VERSION "created by canmatrix"

NS_ :

BS_:

BU_: User ADB_PC_AC01 ADB_PC_BASE ADB_PC_BOX

BO_ 2155937856 AC01_Mode_Set_0_AC01: 1 User
 SG_ mode_0_AC01 : 0|8@1+ (1,0) [0|255] "" ADB_PC_AC01,User

BO_ 2155937857 AC01_Mode_Applied_0_AC01: 1 ADB_PC_AC01
 SG_ mode_0_AC01 : 0|8@1+ (1,0) [0|255] "" User

BO_ 2155937858 AC01_faults_0_AC01: 8 ADB_PC_AC01
 SG_ CABLE_1_2_L1_0_AC01 : 0|1@1+ (1,0) [0|1] "" User
 SG_ CABLE_1_3_L1_0_AC01 : 1|1@1+ (1,0) [0|1] "" User
 SG_ CABLE_1_2_L2_0_AC01 : 2|1@1+ (1,0) [0|1] "" User
 SG_ CABLE_1_3_L2_0_AC01 : 3|1@1+ (1,0) [0|1] "" User
 SG_ CABLE_1_2_L3_0_AC01 : 4|1@1+ (1,0) [0|1] "" User
 SG_ CABLE_1_3_L3_0_AC01 : 5|1@1+ (1,0) [0|1] "" User
 SG_ CABLE_4_5_L1_0_AC01 : 6|1@1+ (1,0) [0|1] "" User
 SG_ CABLE_4_6_L1_0_AC01 : 7|1@1+ (1,0) [0|1] "" User
 SG_ CABLE_4_5_L2_0_AC01 : 8|1@1+ (1,0) [0|1] "" User
 SG_ CABLE_4_6_L2_0_AC01 : 9|1@1+ (1,0) [0|1] "" User
 SG_ CABLE_4_5_L3_0_AC01 : 10|1@1+ (1,0) [0|1] "" User
 SG_ CABLE_4_6_L3_0_AC01 : 11|1@1+ (1,0) [0|1] "" User
 SG_ CABLE_1_4_L1_0_AC01 : 12|1@1+ (1,0) [0|1] "" User
 SG_ CABLE_1_4_L2_0_AC01 : 13|1@1+ (1,0) [0|1] "" User
 SG_ CABLE_1_4_L3_0_AC01 : 14|1@1+ (1,0) [0|1] "" User
 SG_ CABLE_2_3_DC_0_AC01 : 15|1@1+ (1,0) [0|1] "" User
 SG_ CABLE_5_6_DC_0_AC01 : 16|1@1+ (1,0) [0|1] "" User
 SG_ CABLE_3_5_DC_0_AC01 : 17|1@1+ (1,0) [0|1] "" User
 SG_ MODULE_1_RUNNING_0_AC01 : 18|1@1+ (1,0) [0|1] "" User
 SG_ MODULE_2_RUNNING_0_AC01 : 19|1@1+ (1,0) [0|1] "" User
 SG_ MODULE_3_RUNNING_0_AC01 : 20|1@1+ (1,0) [0|1] "" User
 SG_ MODULE_4_RUNNING_0_AC01 : 21|1@1+ (1,0) [0|1] "" User
 SG_ MODULE_5_RUNNING_0_AC01 : 22|1@1+ (1,0) [0|1] "" User
 SG_ MODULE_6_RUNNING_0_AC01 : 23|1@1+ (1,0) [0|1] "" User
 SG_ FILTER_1_RELAY_FAIL_0_AC01 : 24|1@1+ (1,0) [0|1] "" User
 SG_ FILTER_4_RELAY_FAIL_0_AC01 : 25|1@1+ (1,0) [0|1] "" User
 SG_ FILTER_1_RELAY_NOT_OFF_0_AC01 : 26|1@1+ (1,0) [0|1] "" User
 SG_ FILTER_4_RELAY_NOT_OFF_0_AC01 : 27|1@1+ (1,0) [0|1] "" User
 SG_ PRECHARGE_RELAY_CLOSING_0_AC01 : 28|1@1+ (1,0) [0|1] "" User
 SG_ PRECHARGE_RELAY_OPENING_0_AC01 : 29|1@1+ (1,0) [0|1] "" User
 SG_ FILTER_NOT_RUNNING_0_AC01 : 30|1@1+ (1,0) [0|1] "" User
 SG_ RECTIFIER_3P_NOT_RUNNING_0_AC01 : 31|1@1+ (1,0) [0|1] "" User
 SG_ AFE_NOT_OFF_0_AC01 : 32|1@1+ (1,0) [0|1] "" User
 SG_ FILTER_STOP_RUNNING_0_AC01 : 34|1@1+ (1,0) [0|1] "" User
 SG_ RECTIFIER_3P_STOP_RUNNING_0_AC01 : 35|1@1+ (1,0) [0|1] "" User
 SG_ AFE_PWM_NOT_RUNNING_0_AC01 : 36|1@1+ (1,0) [0|1] "" User
 SG_ AFE_PWM_STOP_RUNNING_0_AC01 : 37|1@1+ (1,0) [0|1] "" User
 SG_ BLEEDING_FAILED_0_AC01 : 38|1@1+ (1,0) [0|1] "" User
 SG_ FILTER_NOT_OFF_0_AC01 : 39|1@1+ (1,0) [0|1] "" User

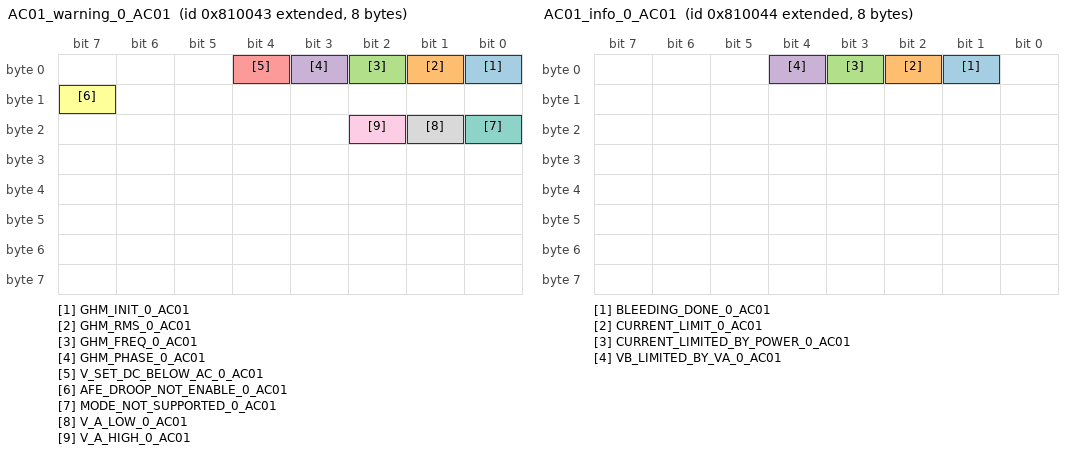
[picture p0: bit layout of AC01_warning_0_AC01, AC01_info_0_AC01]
BO_ 2155937859 AC01_warning_0_AC01: 8 ADB_PC_AC01
 SG_ GHM_INIT_0_AC01 : 0|1@1+ (1,0) [0|1] "" User
 SG_ GHM_RMS_0_AC01 : 1|1@1+ (1,0) [0|1] "" User
 SG_ GHM_FREQ_0_AC01 : 2|1@1+ (1,0) [0|1] "" User
 SG_ GHM_PHASE_0_AC01 : 3|1@1+ (1,0) [0|1] "" User
 SG_ V_SET_DC_BELOW_AC_0_AC01 : 4|1@1+ (1,0) [0|1] "" User
 SG_ AFE_DROOP_NOT_ENABLE_0_AC01 : 15|1@1+ (1,0) [0|1] "" User
 SG_ MODE_NOT_SUPPORTED_0_AC01 : 16|1@1+ (1,0) [0|1] "" User
 SG_ V_A_LOW_0_AC01 : 17|1@1+ (1,0) [0|1] "" User
 SG_ V_A_HIGH_0_AC01 : 18|1@1+ (1,0) [0|1] "" User

BO_ 2155937860 AC01_info_0_AC01: 8 ADB_PC_AC01
 SG_ BLEEDING_DONE_0_AC01 : 1|1@1+ (1,0) [0|1] "" User
 SG_ CURRENT_LIMIT_0_AC01 : 2|1@1+ (1,0) [0|1] "" User
 SG_ CURRENT_LIMITED_BY_POWER_0_AC01 : 3|1@1+ (1,0) [0|1] "" User
 SG_ VB_LIMITED_BY_VA_0_AC01 : 4|1@1+ (1,0) [0|1] "" User

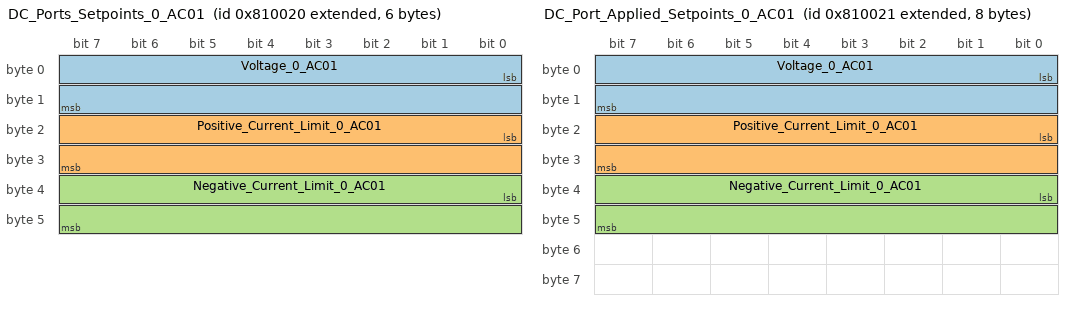
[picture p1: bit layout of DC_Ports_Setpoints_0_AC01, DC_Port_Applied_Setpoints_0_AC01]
BO_ 2155937824 DC_Ports_Setpoints_0_AC01: 6 User
 SG_ Voltage_0_AC01 : 0|16@1+ (0.1,0) [0|6553.5] "V" ADB_PC_AC01,User
 SG_ Positive_Current_Limit_0_AC01 : 16|16@1- (0.1,0) [-3276.8|3276.7] "A" ADB_PC_AC01,User
 SG_ Negative_Current_Limit_0_AC01 : 32|16@1- (0.1,0) [-3276.8|3276.7] "A" ADB_PC_AC01,User

BO_ 2155937825 DC_Port_Applied_Setpoints_0_AC01: 8 ADB_PC_AC01
 SG_ Voltage_0_AC01 : 0|16@1+ (0.1,0) [0|6553.5] "V" User
 SG_ Positive_Current_Limit_0_AC01 : 16|16@1- (0.1,0) [-3276.8|3276.7] "A" User
 SG_ Negative_Current_Limit_0_AC01 : 32|16@1- (0.1,0) [-3276.8|3276.7] "A" User

BO_ 2155937828 DC_Port_Measurements_0_AC01: 4 ADB_PC_AC01
 SG_ Voltage_0_AC01 : 0|16@1+ (0.1,0) [0|6553.5] "V" User
 SG_ Current_0_AC01 : 16|16@1- (0.1,0) [-3276.8|3276.7] "A" User

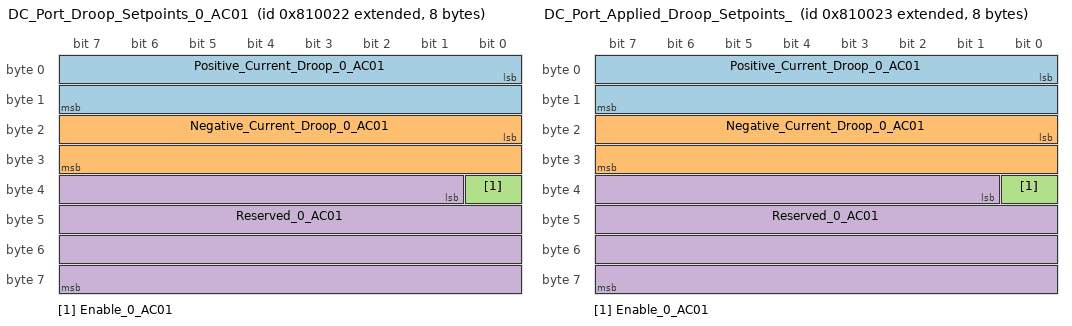
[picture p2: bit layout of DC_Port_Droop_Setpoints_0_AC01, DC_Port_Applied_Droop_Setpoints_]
BO_ 2155937826 DC_Port_Droop_Setpoints_0_AC01: 8 User
 SG_ Positive_Current_Droop_0_AC01 : 0|16@1+ (0.01,0) [0.00|655.35] "Ohm" ADB_PC_AC01,User
 SG_ Negative_Current_Droop_0_AC01 : 16|16@1+ (0.01,0) [0.00|655.35] "Ohm" ADB_PC_AC01,User
 SG_ Enable_0_AC01 : 32|1@1+ (1,0) [0|1] "" ADB_PC_AC01,User
 SG_ Reserved_0_AC01 : 33|31@1+ (1,0) [0|2147483647] "" ADB_PC_AC01,User

BO_ 2155937827 DC_Port_Applied_Droop_Setpoints_: 8 ADB_PC_AC01
 SG_ Positive_Current_Droop_0_AC01 : 0|16@1+ (0.01,0) [0.00|655.35] "Ohm" User
 SG_ Negative_Current_Droop_0_AC01 : 16|16@1+ (0.01,0) [0.00|655.35] "Ohm" User
 SG_ Enable_0_AC01 : 32|1@1+ (1,0) [0|1] "" User
 SG_ Reserved_0_AC01 : 33|31@1+ (1,0) [0|2147483647] "" User

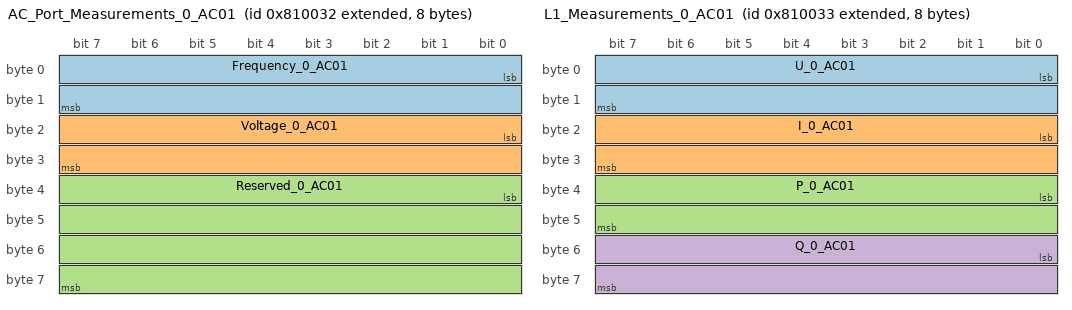
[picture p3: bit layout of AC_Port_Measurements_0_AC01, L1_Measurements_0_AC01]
BO_ 2155937842 AC_Port_Measurements_0_AC01: 8 ADB_PC_AC01
 SG_ Frequency_0_AC01 : 0|16@1+ (0.01,0) [0.00|655.35] "Hz" User
 SG_ Voltage_0_AC01 : 16|16@1+ (0.1,0) [0|6553.5] "V" User
 SG_ Reserved_0_AC01 : 32|32@1+ (1,0) [0|4294967295] "" User

BO_ 2155937843 L1_Measurements_0_AC01: 8 ADB_PC_AC01
 SG_ U_0_AC01 : 0|16@1- (0.1,0) [-3276.8|3276.7] "V" User
 SG_ I_0_AC01 : 16|16@1- (0.1,0) [-3276.8|3276.7] "A" User
 SG_ P_0_AC01 : 32|16@1- (0.1,0) [-3276.8|3276.7] "W" User
 SG_ Q_0_AC01 : 48|16@1- (0.1,0) [-3276.8|3276.7] "VAR" User,ADB_PC_AC01

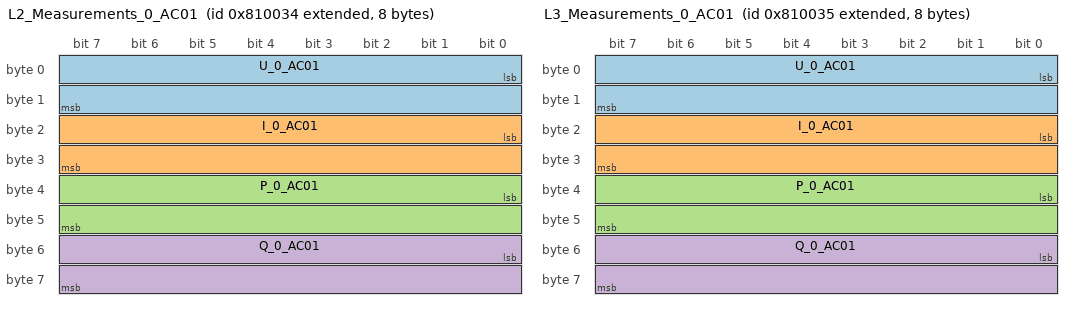
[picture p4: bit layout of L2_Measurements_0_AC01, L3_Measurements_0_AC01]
BO_ 2155937844 L2_Measurements_0_AC01: 8 ADB_PC_AC01
 SG_ U_0_AC01 : 0|16@1- (0.1,0) [-3276.8|3276.7] "V" User
 SG_ I_0_AC01 : 16|16@1- (0.1,0) [-3276.8|3276.7] "A" User
 SG_ P_0_AC01 : 32|16@1- (0.1,0) [-3276.8|3276.7] "W" User
 SG_ Q_0_AC01 : 48|16@1- (0.1,0) [-3276.8|3276.7] "VAR" User

BO_ 2155937845 L3_Measurements_0_AC01: 8 ADB_PC_AC01
 SG_ U_0_AC01 : 0|16@1- (0.1,0) [-3276.8|3276.7] "V" User
 SG_ I_0_AC01 : 16|16@1- (0.1,0) [-3276.8|3276.7] "A" User
 SG_ P_0_AC01 : 32|16@1- (0.1,0) [-3276.8|3276.7] "W" User
 SG_ Q_0_AC01 : 48|16@1- (0.1,0) [-3276.8|3276.7] "VAR" User

BO_ 2155937840 AC_Port_Setpoints_0_AC01: 8 User
 SG_ Q_0_AC01 : 0|16@1- (10,0) [-327680|327670] "VAR" ADB_PC_AC01
 SG_ Reserved_0_AC01 : 16|48@1+ (1,0) [0|281474976710655] "" ADB_PC_AC01

BO_ 2155937841 AC_Port_Applied_Setpoints_0_AC01: 8 ADB_PC_AC01
 SG_ Q_0_AC01 : 0|16@1- (10,0) [-327680|327670] "VAR" User
 SG_ Reserved_0_AC01 : 16|48@1+ (1,0) [0|281474976710655] "" User

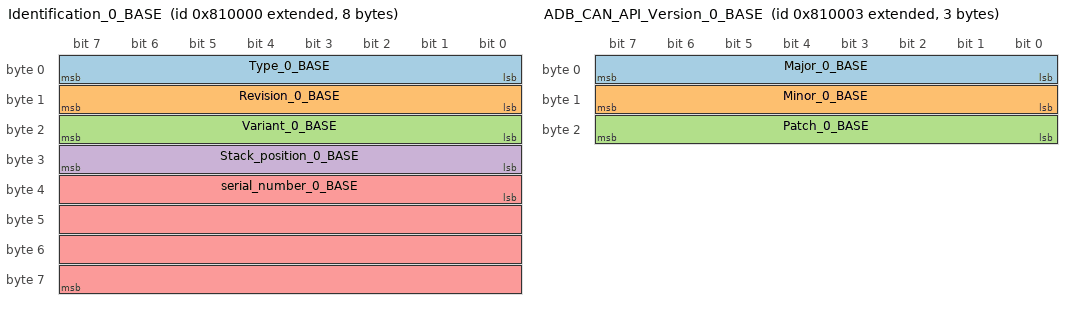
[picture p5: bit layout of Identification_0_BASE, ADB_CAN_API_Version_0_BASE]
BO_ 2155937792 Identification_0_BASE: 8 ADB_PC_BASE
 SG_ Type_0_BASE : 0|8@1+ (1,0) [0|255] "" User
 SG_ Revision_0_BASE : 8|8@1+ (1,0) [0|255] "" User
 SG_ Variant_0_BASE : 16|8@1+ (1,0) [0|255] "" User
 SG_ Stack_position_0_BASE : 24|8@1+ (1,0) [0|255] "" User,ADB_PC_BASE
 SG_ serial_number_0_BASE : 32|32@1+ (1,0) [0|4294967295] "" User

BO_ 2155937794 Firmware_UID_0_BASE: 8 ADB_PC_BASE
 SG_ UID_0_BASE : 0|64@1+ (1,0) [0|1.844674407370955E+019] "" User

BO_ 2155937793 Bootloader_UID_0_BASE: 8 ADB_PC_BASE
 SG_ UID_0_BASE : 0|64@1+ (1,0) [0|1.844674407370955E+019] "" User

BO_ 2155937795 ADB_CAN_API_Version_0_BASE: 3 ADB_PC_BASE
 SG_ Major_0_BASE : 0|8@1+ (1,0) [0|255] "" User
 SG_ Minor_0_BASE : 8|8@1+ (1,0) [0|255] "" User
 SG_ Patch_0_BASE : 16|8@1+ (1,0) [0|255] "" User

BO_ 2155937861 Stack_Control_0_BASE: 6 User
 SG_ Stack_position_0_BASE : 0|8@1+ (1,0) [0|255] "" ADB_PC_BASE
 SG_ reserved_0_BASE : 8|8@1+ (1,0) [0|255] "" ADB_PC_BASE
 SG_ SN_number_0_BASE : 16|32@1+ (1,0) [0|4294967295] "" ADB_PC_BASE

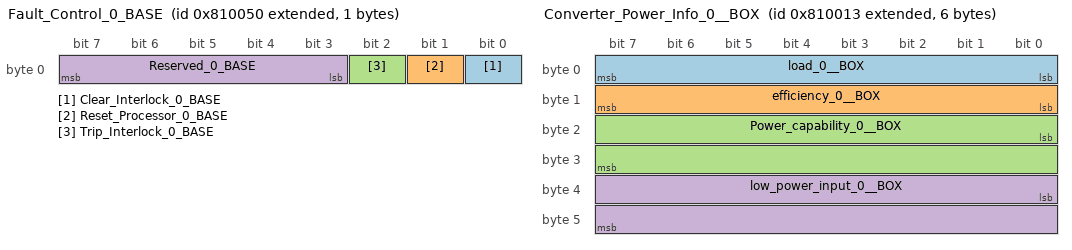
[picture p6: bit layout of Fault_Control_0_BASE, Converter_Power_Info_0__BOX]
BO_ 2155937872 Fault_Control_0_BASE: 1 User
 SG_ Clear_Interlock_0_BASE : 0|1@1+ (1,0) [0|1] "" ADB_PC_BASE
 SG_ Reset_Processor_0_BASE : 1|1@1+ (1,0) [0|1] "" ADB_PC_BASE
 SG_ Trip_Interlock_0_BASE : 2|1@1+ (1,0) [0|1] "" ADB_PC_BASE
 SG_ Reserved_0_BASE : 3|5@1+ (1,0) [0|31] "" ADB_PC_BASE

BO_ 2155937889 Factory_Control_0_BASE: 8 User
 SG_ Factory_mode_0_BASE : 0|1@1+ (1,0) [0|1] "" ADB_PC_BASE

BO_ 2155937810 Converter_Control_0__BOX: 1 User
 SG_ enable_0__BOX : 0|1@1+ (1,0) [0|1] "" ADB_PC_BOX

BO_ 2155937811 Converter_Power_Info_0__BOX: 6 ADB_PC_BOX
 SG_ load_0__BOX : 0|8@1+ (1,0) [0|255] "%" User
 SG_ efficiency_0__BOX : 8|8@1+ (1,0) [0|255] "%" User
 SG_ Power_capability_0__BOX : 16|16@1- (0.1,0) [-3276.8|3276.7] "kw" User
 SG_ low_power_input_0__BOX : 32|16@1- (0.01,0) [-327.68|327.67] "v" User

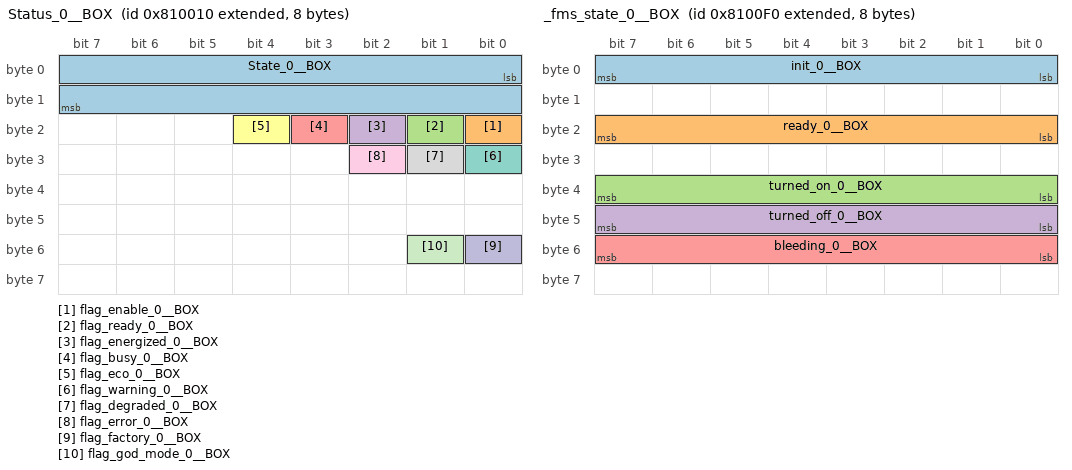
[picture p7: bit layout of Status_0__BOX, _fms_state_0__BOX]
BO_ 2155937808 Status_0__BOX: 8 ADB_PC_BOX
 SG_ State_0__BOX : 0|16@1+ (1,0) [0|65535] "" User
 SG_ flag_enable_0__BOX : 16|1@1+ (1,0) [0|1] "" User
 SG_ flag_ready_0__BOX : 17|1@1+ (1,0) [0|1] "" User
 SG_ flag_energized_0__BOX : 18|1@1+ (1,0) [0|1] "" User
 SG_ flag_busy_0__BOX : 19|1@1+ (1,0) [0|1] "" User
 SG_ flag_eco_0__BOX : 20|1@1+ (1,0) [0|1] "" User
 SG_ flag_warning_0__BOX : 24|1@1+ (1,0) [0|1] "" User
 SG_ flag_degraded_0__BOX : 25|1@1+ (1,0) [0|1] "" User
 SG_ flag_error_0__BOX : 26|1@1+ (1,0) [0|1] "" User
 SG_ flag_factory_0__BOX : 48|1@1+ (1,0) [0|1] "" User
 SG_ flag_god_mode_0__BOX : 49|1@1+ (1,0) [0|1] "" User

BO_ 2155938032 _fms_state_0__BOX: 8 ADB_PC_BOX
 SG_ init_0__BOX : 0|8@1+ (1,0) [0|255] "" User
 SG_ ready_0__BOX : 16|8@1+ (1,0) [0|255] "" User
 SG_ turned_on_0__BOX : 32|8@1+ (1,0) [0|255] "" User
 SG_ turned_off_0__BOX : 40|8@1+ (1,0) [0|255] "" User
 SG_ bleeding_0__BOX : 48|8@1+ (1,0) [0|255] "" User

BO_ 2155937809 Faults_0__BOX: 8 ADB_PC_BOX
 SG_ internal_0__BOX : 0|1@1+ (1,0) [0|1] "" User
 SG_ external_0__BOX : 1|1@1+ (1,0) [0|1] "" User
 SG_ system_0__BOX : 2|1@1+ (1,0) [0|1] "" User
 SG_ EEPROM_failure_0__BOX : 3|1@1+ (1,0) [0|1] "" User
 SG_ wrong_nfo_0__BOX : 4|1@1+ (1,0) [0|1] "" User
 SG_ Measurement_system_failure_0__BO : 5|1@1+ (1,0) [0|1] "" User
 SG_ PLL_not_locked_0__BOX : 6|1@1+ (1,0) [0|1] "" User
 SG_ overtemperature_0__BOX : 7|1@1+ (1,0) [0|1] "" User
 SG_ fan_stuck_0__BOX : 8|1@1+ (1,0) [0|1] "" User
 SG_ dead_module_0__BOX : 9|1@1+ (1,0) [0|1] "" User
 SG_ keep_alive_not_serv_internal_0__ : 10|1@1+ (1,0) [0|1] "" User
 SG_ error_temperature_0__BOX : 11|1@1+ (1,0) [0|1] "" User
 SG_ internal_modules_ready_0__BOX : 12|1@1+ (1,0) [0|1] "" User
 SG_ internal_modules_can_api_0__BOX : 13|1@1+ (1,0) [0|1] "" User
 SG_ internal_modules_missing_0__BOX : 14|1@1+ (1,0) [0|1] "" User
 SG_ internal_modules_wrong_0__BOX : 15|1@1+ (1,0) [0|1] "" User
 SG_ internal_modules_stack_0__BOX : 16|1@1+ (1,0) [0|1] "" User
 SG_ internal_modules_init_0__BOX : 17|1@1+ (1,0) [0|1] "" User
 SG_ wrong_revision_0__BOX : 18|1@1+ (1,0) [0|1] "" User
 SG_ v_in_low_0__BOX : 19|1@1+ (1,0) [0|1] "" User
 SG_ v_in_critical_0__BOX : 20|1@1+ (1,0) [0|1] "" User
 SG_ keep_alive_not_serv_0__BOX : 21|1@1+ (1,0) [0|1] "" User

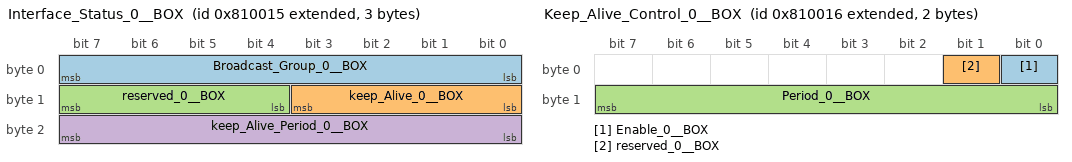
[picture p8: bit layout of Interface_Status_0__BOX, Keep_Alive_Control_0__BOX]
BO_ 2155937813 Interface_Status_0__BOX: 3 ADB_PC_BOX
 SG_ Broadcast_Group_0__BOX : 0|8@1+ (1,0) [0|30] "" User
 SG_ keep_Alive_0__BOX : 8|4@1+ (1,0) [0|15] "" User
 SG_ reserved_0__BOX : 12|4@1+ (1,0) [0|15] "" User
 SG_ keep_Alive_Period_0__BOX : 16|8@1+ (0.1,0) [0|25.5] "s" User

BO_ 2155937814 Keep_Alive_Control_0__BOX: 2 User
 SG_ Enable_0__BOX : 0|1@1+ (1,0) [0|1] "" ADB_PC_BOX
 SG_ reserved_0__BOX : 1|1@1+ (1,0) [0|1] "" User
 SG_ Period_0__BOX : 8|8@1+ (0.1,0) [0|25.5] "s" User

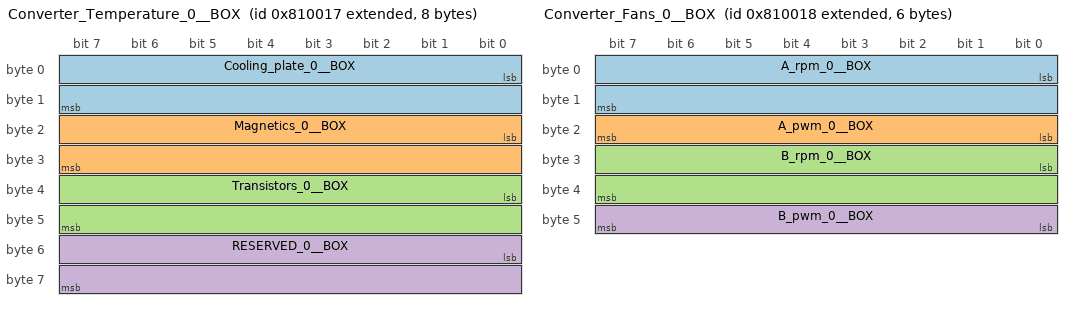
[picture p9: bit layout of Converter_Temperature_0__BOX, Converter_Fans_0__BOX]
BO_ 2155937815 Converter_Temperature_0__BOX: 8 ADB_PC_BOX
 SG_ Cooling_plate_0__BOX : 0|16@1- (0.01,0) [-327.68|327.67] "°C" User
 SG_ Magnetics_0__BOX : 16|16@1- (0.01,0) [-327.68|327.67] "°C" User
 SG_ Transistors_0__BOX : 32|16@1- (0.01,0) [-327.68|327.67] "°C" User
 SG_ RESERVED_0__BOX : 48|16@1- (0.01,0) [-327.68|327.67] "°C" User

BO_ 2155937816 Converter_Fans_0__BOX: 6 ADB_PC_BOX
 SG_ A_rpm_0__BOX : 0|16@1+ (1,0) [0|65535] "rpm" User
 SG_ A_pwm_0__BOX : 16|8@1+ (1,0) [0|255] "%" User
 SG_ B_rpm_0__BOX : 24|16@1+ (1,0) [0|65535] "rpm" User
 SG_ B_pwm_0__BOX : 40|8@1+ (1,0) [0|255] "%" User

BO_ 2155937817 Keep_Alive_Feed_0__BOX: 1 User
 SG_ feed_0__BOX : 0|1@1+ (1,0) [0|1] "" ADB_PC_BOX

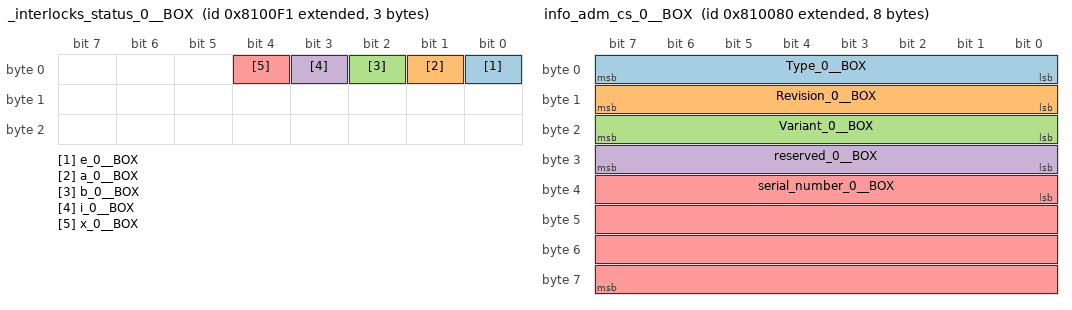
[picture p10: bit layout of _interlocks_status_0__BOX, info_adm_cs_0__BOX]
BO_ 2155938033 _interlocks_status_0__BOX: 3 ADB_PC_BOX
 SG_ e_0__BOX : 0|1@1+ (1,0) [0|1] "" User
 SG_ a_0__BOX : 1|1@1+ (1,0) [0|1] "" User
 SG_ b_0__BOX : 2|1@1+ (1,0) [0|1] "" User
 SG_ i_0__BOX : 3|1@1+ (1,0) [0|1] "" User
 SG_ x_0__BOX : 4|1@1+ (1,0) [0|1] "" User

BO_ 2155937812 Broadcast_Group_Control_0__BOX: 1 User
 SG_ Group_ID_0__BOX : 0|8@1+ (1,0) [0|255] "" ADB_PC_BOX

BO_ 2155937920 info_adm_cs_0__BOX: 8 ADB_PC_BOX
 SG_ Type_0__BOX : 0|8@1+ (1,0) [0|255] "" User
 SG_ Revision_0__BOX : 8|8@1+ (1,0) [0|255] "" User
 SG_ Variant_0__BOX : 16|8@1+ (1,0) [0|255] "" User
 SG_ reserved_0__BOX : 24|8@1+ (1,0) [0|255] "" User
 SG_ serial_number_0__BOX : 32|32@1+ (1,0) [0|4294967295] "" User

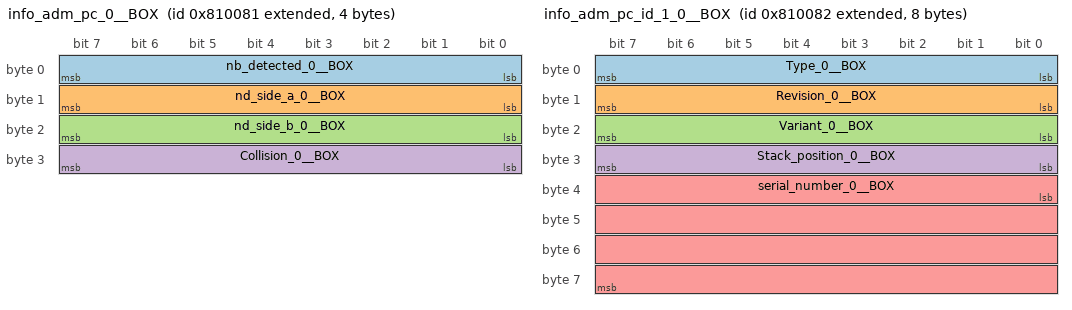
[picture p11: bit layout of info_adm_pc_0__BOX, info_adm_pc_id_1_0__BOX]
BO_ 2155937921 info_adm_pc_0__BOX: 4 ADB_PC_BOX
 SG_ nb_detected_0__BOX : 0|8@1+ (1,0) [0|255] "" User
 SG_ nd_side_a_0__BOX : 8|8@1+ (1,0) [0|255] "" User
 SG_ nd_side_b_0__BOX : 16|8@1+ (1,0) [0|255] "" User
 SG_ Collision_0__BOX : 24|8@1+ (1,0) [0|255] "" User

BO_ 2155937922 info_adm_pc_id_1_0__BOX: 8 ADB_PC_BOX
 SG_ Type_0__BOX : 0|8@1+ (1,0) [0|255] "" User
 SG_ Revision_0__BOX : 8|8@1+ (1,0) [0|255] "" User
 SG_ Variant_0__BOX : 16|8@1+ (1,0) [0|255] "" User
 SG_ Stack_position_0__BOX : 24|8@1+ (1,0) [0|255] "" User
 SG_ serial_number_0__BOX : 32|32@1+ (1,0) [0|4294967295] "" User

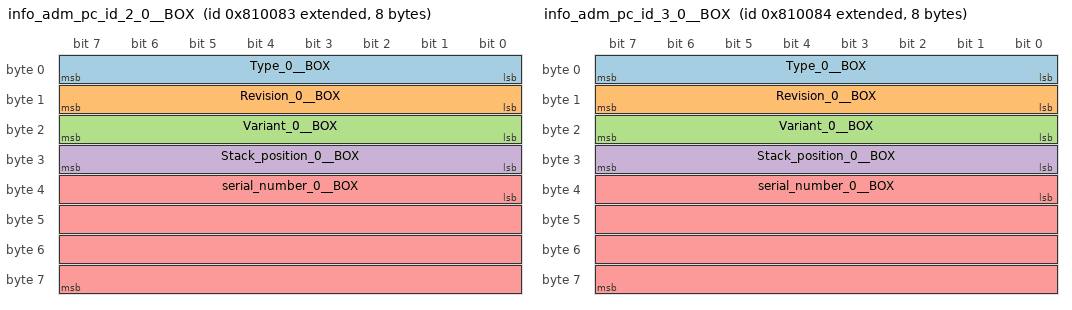
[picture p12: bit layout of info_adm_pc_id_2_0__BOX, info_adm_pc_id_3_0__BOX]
BO_ 2155937923 info_adm_pc_id_2_0__BOX: 8 ADB_PC_BOX
 SG_ Type_0__BOX : 0|8@1+ (1,0) [0|255] "" User
 SG_ Revision_0__BOX : 8|8@1+ (1,0) [0|255] "" User
 SG_ Variant_0__BOX : 16|8@1+ (1,0) [0|255] "" User
 SG_ Stack_position_0__BOX : 24|8@1+ (1,0) [0|255] "" User
 SG_ serial_number_0__BOX : 32|32@1+ (1,0) [0|4294967295] "" User

BO_ 2155937924 info_adm_pc_id_3_0__BOX: 8 ADB_PC_BOX
 SG_ Type_0__BOX : 0|8@1+ (1,0) [0|255] "" User
 SG_ Revision_0__BOX : 8|8@1+ (1,0) [0|255] "" User
 SG_ Variant_0__BOX : 16|8@1+ (1,0) [0|255] "" User
 SG_ Stack_position_0__BOX : 24|8@1+ (1,0) [0|255] "" User
 SG_ serial_number_0__BOX : 32|32@1+ (1,0) [0|4294967295] "" User

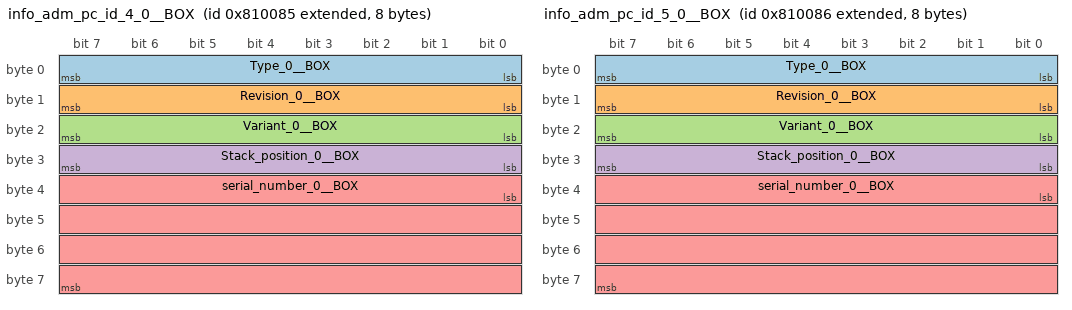
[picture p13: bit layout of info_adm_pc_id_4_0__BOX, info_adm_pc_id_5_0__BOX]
BO_ 2155937925 info_adm_pc_id_4_0__BOX: 8 ADB_PC_BOX
 SG_ Type_0__BOX : 0|8@1+ (1,0) [0|255] "" User
 SG_ Revision_0__BOX : 8|8@1+ (1,0) [0|255] "" User
 SG_ Variant_0__BOX : 16|8@1+ (1,0) [0|255] "" User
 SG_ Stack_position_0__BOX : 24|8@1+ (1,0) [0|255] "" User
 SG_ serial_number_0__BOX : 32|32@1+ (1,0) [0|4294967295] "" User

BO_ 2155937926 info_adm_pc_id_5_0__BOX: 8 ADB_PC_BOX
 SG_ Type_0__BOX : 0|8@1+ (1,0) [0|255] "" User
 SG_ Revision_0__BOX : 8|8@1+ (1,0) [0|255] "" User
 SG_ Variant_0__BOX : 16|8@1+ (1,0) [0|255] "" User
 SG_ Stack_position_0__BOX : 24|8@1+ (1,0) [0|255] "" User
 SG_ serial_number_0__BOX : 32|32@1+ (1,0) [0|4294967295] "" User

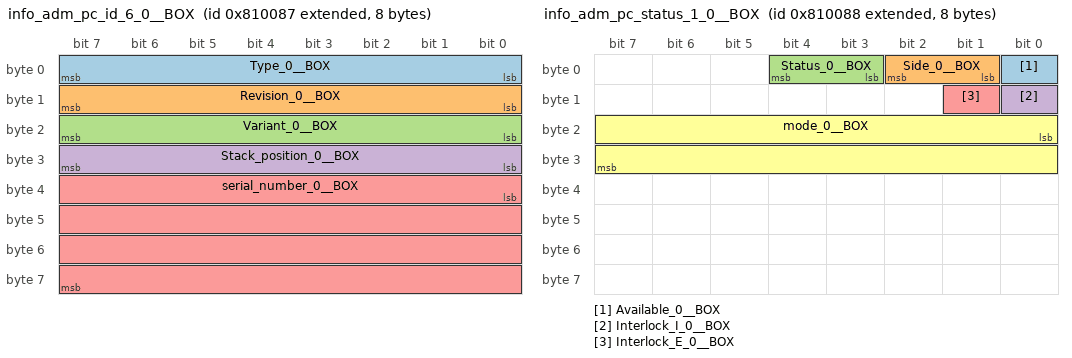
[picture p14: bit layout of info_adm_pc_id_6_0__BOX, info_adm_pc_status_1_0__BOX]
BO_ 2155937927 info_adm_pc_id_6_0__BOX: 8 ADB_PC_BOX
 SG_ Type_0__BOX : 0|8@1+ (1,0) [0|255] "" User
 SG_ Revision_0__BOX : 8|8@1+ (1,0) [0|255] "" User
 SG_ Variant_0__BOX : 16|8@1+ (1,0) [0|255] "" User
 SG_ Stack_position_0__BOX : 24|8@1+ (1,0) [0|255] "" User
 SG_ serial_number_0__BOX : 32|32@1+ (1,0) [0|4294967295] "" User

BO_ 2155937928 info_adm_pc_status_1_0__BOX: 8 ADB_PC_BOX
 SG_ Available_0__BOX : 0|1@1+ (1,0) [0|1] "" User
 SG_ Side_0__BOX : 1|2@1+ (1,0) [0|3] "" User
 SG_ Status_0__BOX : 3|2@1+ (1,0) [0|3] "" User
 SG_ Interlock_I_0__BOX : 8|1@1+ (1,0) [0|1] "" User
 SG_ Interlock_E_0__BOX : 9|1@1+ (1,0) [0|1] "" User
 SG_ mode_0__BOX : 16|16@1+ (1,0) [0|65535] "" User

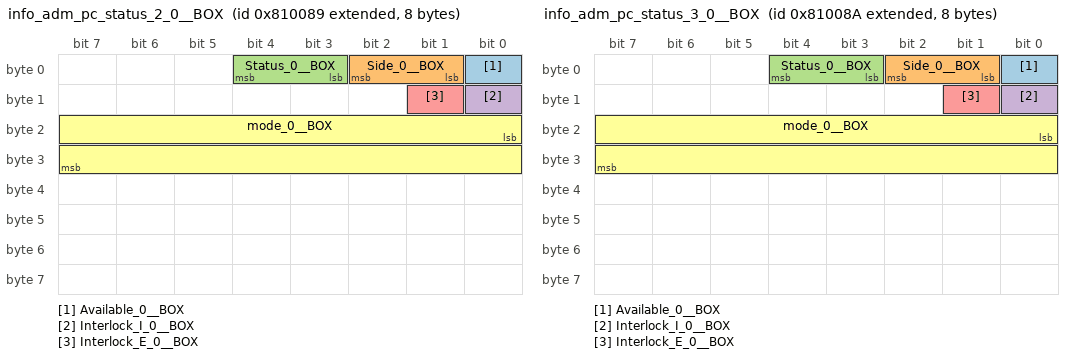
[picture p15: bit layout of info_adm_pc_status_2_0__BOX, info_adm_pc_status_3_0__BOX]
BO_ 2155937929 info_adm_pc_status_2_0__BOX: 8 ADB_PC_BOX
 SG_ Available_0__BOX : 0|1@1+ (1,0) [0|1] "" User
 SG_ Side_0__BOX : 1|2@1+ (1,0) [0|3] "" User
 SG_ Status_0__BOX : 3|2@1+ (1,0) [0|3] "" User
 SG_ Interlock_I_0__BOX : 8|1@1+ (1,0) [0|1] "" User
 SG_ Interlock_E_0__BOX : 9|1@1+ (1,0) [0|1] "" User
 SG_ mode_0__BOX : 16|16@1+ (1,0) [0|65535] "" User

BO_ 2155937930 info_adm_pc_status_3_0__BOX: 8 ADB_PC_BOX
 SG_ Available_0__BOX : 0|1@1+ (1,0) [0|1] "" User
 SG_ Side_0__BOX : 1|2@1+ (1,0) [0|3] "" User
 SG_ Status_0__BOX : 3|2@1+ (1,0) [0|3] "" User
 SG_ Interlock_I_0__BOX : 8|1@1+ (1,0) [0|1] "" User
 SG_ Interlock_E_0__BOX : 9|1@1+ (1,0) [0|1] "" User
 SG_ mode_0__BOX : 16|16@1+ (1,0) [0|65535] "" User

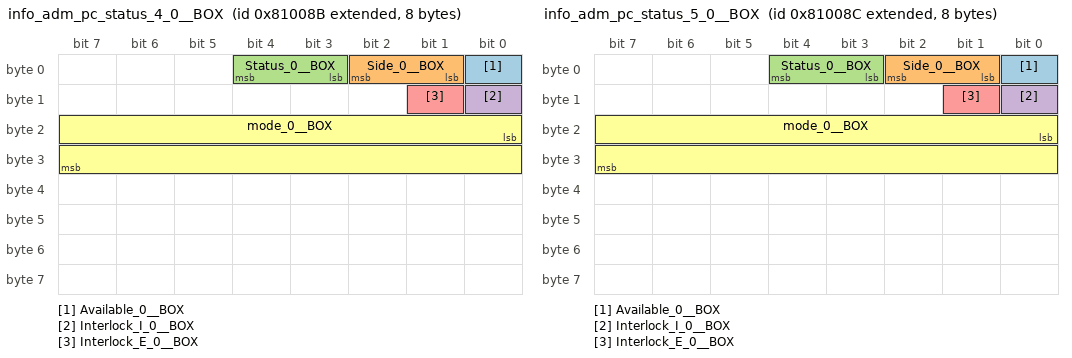
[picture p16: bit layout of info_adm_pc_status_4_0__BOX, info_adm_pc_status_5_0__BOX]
BO_ 2155937931 info_adm_pc_status_4_0__BOX: 8 ADB_PC_BOX
 SG_ Available_0__BOX : 0|1@1+ (1,0) [0|1] "" User
 SG_ Side_0__BOX : 1|2@1+ (1,0) [0|3] "" User
 SG_ Status_0__BOX : 3|2@1+ (1,0) [0|3] "" User
 SG_ Interlock_I_0__BOX : 8|1@1+ (1,0) [0|1] "" User
 SG_ Interlock_E_0__BOX : 9|1@1+ (1,0) [0|1] "" User
 SG_ mode_0__BOX : 16|16@1+ (1,0) [0|65535] "" User

BO_ 2155937932 info_adm_pc_status_5_0__BOX: 8 ADB_PC_BOX
 SG_ Available_0__BOX : 0|1@1+ (1,0) [0|1] "" User
 SG_ Side_0__BOX : 1|2@1+ (1,0) [0|3] "" User
 SG_ Status_0__BOX : 3|2@1+ (1,0) [0|3] "" User
 SG_ Interlock_I_0__BOX : 8|1@1+ (1,0) [0|1] "" User
 SG_ Interlock_E_0__BOX : 9|1@1+ (1,0) [0|1] "" User
 SG_ mode_0__BOX : 16|16@1+ (1,0) [0|65535] "" User

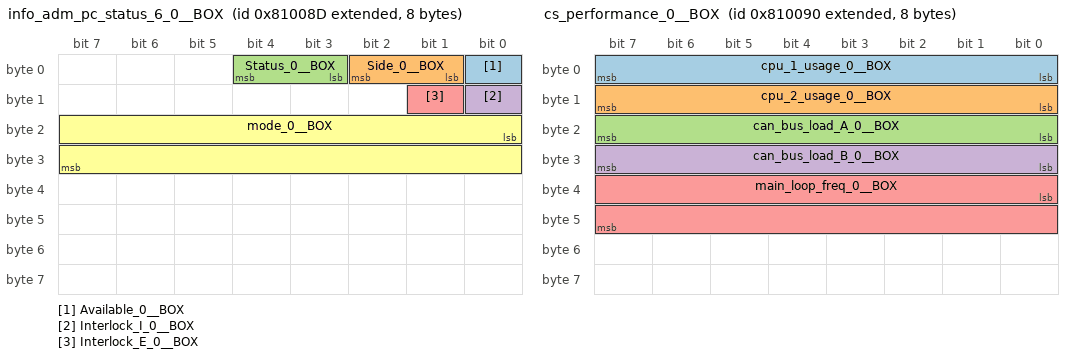
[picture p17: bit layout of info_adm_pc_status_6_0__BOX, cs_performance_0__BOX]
BO_ 2155937933 info_adm_pc_status_6_0__BOX: 8 ADB_PC_BOX
 SG_ Available_0__BOX : 0|1@1+ (1,0) [0|1] "" User
 SG_ Side_0__BOX : 1|2@1+ (1,0) [0|3] "" User
 SG_ Status_0__BOX : 3|2@1+ (1,0) [0|3] "" User
 SG_ Interlock_I_0__BOX : 8|1@1+ (1,0) [0|1] "" User
 SG_ Interlock_E_0__BOX : 9|1@1+ (1,0) [0|1] "" User
 SG_ mode_0__BOX : 16|16@1+ (1,0) [0|65535] "" User

BO_ 2155937936 cs_performance_0__BOX: 8 ADB_PC_BOX
 SG_ cpu_1_usage_0__BOX : 0|8@1+ (1,0) [0|255] "%" User
 SG_ cpu_2_usage_0__BOX : 8|8@1+ (1,0) [0|255] "%" User
 SG_ can_bus_load_A_0__BOX : 16|8@1+ (1,0) [0|255] "%" User
 SG_ can_bus_load_B_0__BOX : 24|8@1+ (1,0) [0|255] "%" User
 SG_ main_loop_freq_0__BOX : 32|16@1+ (1,0) [0|65535] "Hz" User

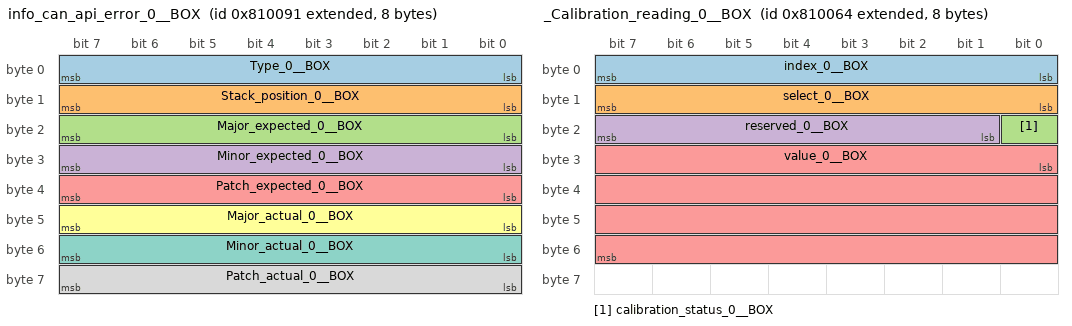
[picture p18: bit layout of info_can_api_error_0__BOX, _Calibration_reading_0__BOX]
BO_ 2155937937 info_can_api_error_0__BOX: 8 ADB_PC_BOX
 SG_ Type_0__BOX : 0|8@1+ (1,0) [0|255] "" User
 SG_ Stack_position_0__BOX : 8|8@1+ (1,0) [0|255] "" User
 SG_ Major_expected_0__BOX : 16|8@1+ (1,0) [0|255] "" User
 SG_ Minor_expected_0__BOX : 24|8@1+ (1,0) [0|255] "" User
 SG_ Patch_expected_0__BOX : 32|8@1+ (1,0) [0|255] "" User
 SG_ Major_actual_0__BOX : 40|8@1+ (1,0) [0|255] "" User
 SG_ Minor_actual_0__BOX : 48|8@1+ (1,0) [0|255] "" User
 SG_ Patch_actual_0__BOX : 56|8@1+ (1,0) [0|255] "" User

BO_ 2155937890 _Calibration_writing_0__BOX: 6 User
 SG_ index_0__BOX : 0|8@1+ (1,0) [0|255] "" ADB_PC_BOX,User
 SG_ select_0__BOX : 8|8@1+ (1,0) [0|255] "" ADB_PC_BOX,User
 SG_ value_0__BOX : 16|32@1- (0.0001,0) [-214748.3648|214748.3647] "" ADB_PC_BOX,User

BO_ 2155937891 _Calibration_reading_cmd_0__BOX: 2 User
 SG_ index_0__BOX : 0|8@1+ (1,0) [0|255] "" ADB_PC_BOX
 SG_ select_0__BOX : 8|8@1+ (1,0) [0|255] "" ADB_PC_BOX

BO_ 2155937892 _Calibration_reading_0__BOX: 8 ADB_PC_BOX
 SG_ index_0__BOX : 0|8@1+ (1,0) [0|255] "" User
 SG_ select_0__BOX : 8|8@1+ (1,0) [0|255] "" User
 SG_ calibration_status_0__BOX : 16|1@1+ (1,0) [0|1] "" User
 SG_ reserved_0__BOX : 17|7@1+ (1,0) [0|127] "" User
 SG_ value_0__BOX : 24|32@1- (0.0001,0) [-214748.3648|214748.3647] "" User

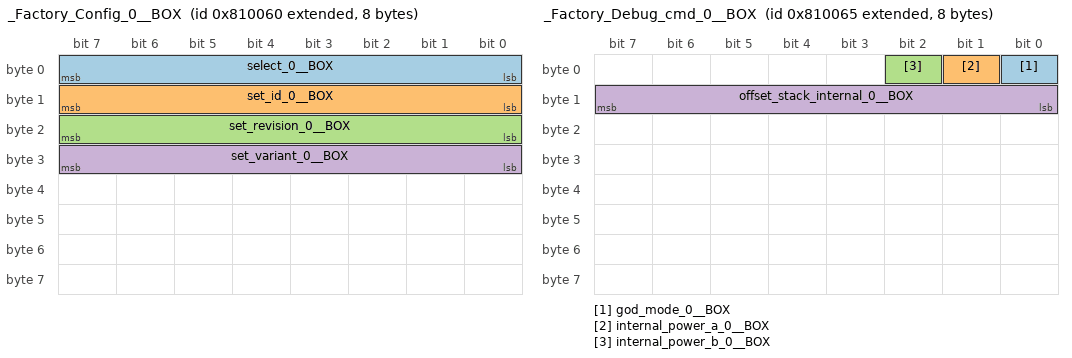
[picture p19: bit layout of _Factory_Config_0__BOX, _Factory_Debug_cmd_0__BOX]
BO_ 2155937888 _Factory_Config_0__BOX: 8 User
 SG_ select_0__BOX : 0|8@1+ (1,0) [0|255] "" ADB_PC_BOX
 SG_ set_id_0__BOX : 8|8@1+ (1,0) [0|255] "" ADB_PC_BOX
 SG_ set_revision_0__BOX : 16|8@1+ (1,0) [0|255] "" ADB_PC_BOX
 SG_ set_variant_0__BOX : 24|8@1+ (1,0) [0|255] "" ADB_PC_BOX

BO_ 2155937893 _Factory_Debug_cmd_0__BOX: 8 User
 SG_ god_mode_0__BOX : 0|1@1+ (1,0) [0|1] "" ADB_PC_BOX
 SG_ internal_power_a_0__BOX : 1|1@1+ (1,0) [0|1] "" ADB_PC_BOX
 SG_ internal_power_b_0__BOX : 2|1@1+ (1,0) [0|1] "" ADB_PC_BOX
 SG_ offset_stack_internal_0__BOX : 8|8@1+ (1,0) [0|255] "offset" ADB_PC_BOX

CM_ BO_ 2155937856  "Set the mode of AC01";
CM_ BO_ 2155937857  "read back the modes";
CM_ BO_ 2155937858  "AC01 Critical and Error Faults";
CM_ BO_ 2155937859  "AC01 Warning";
CM_ BO_ 2155937860  "AC01 Info";
CM_ BO_ 2155937824  "The setpoints control the behaviour of the DC Port of the AC01. The AC01 operates this port in CVCC mode";
CM_ BO_ 2155937825  "The setpoints that are currently used by the AC01. This message allows to validate that the setpoints have been properly applied.";
CM_ BO_ 2155937828  "Measurements of the DC Bus";
CM_ BO_ 2155937826  "Setpoints for applying Droop on the DC Port. Droop is needed for paralleling multiple AC01";
CM_ BO_ 2155937827  "Droop setpoints that are applied by the AC01";
CM_ BO_ 2155937842  "Mesured values of the Grid connection";
CM_ BO_ 2155937843  "Measurements for L1 of the AC port";
CM_ BO_ 2155937844  "Measurements for L2 of the AC port";
CM_ BO_ 2155937845  "Measurements for L3 of the AC port";
CM_ BO_ 2155937840  "Setpoints to apply to the AC Port";
CM_ BO_ 2155937841  "Setpoints that are currently being applied to the the AC Port";
CM_ BO_ 2155937792  "Identification of the device";
CM_ BO_ 2155937794  "Unique Identifier of the Firmware used on this module";
CM_ BO_ 2155937793  "Unique Identifier of the Bootloader used on this module";
CM_ BO_ 2155937795  "This message declares the version of the API that is provided by the converter. The version follows newer convention, as this file is an API definition, patch does not apply";
CM_ BO_ 2155937861  "Module stack control";
CM_ BO_ 2155937872  "Fault Control: actions to clear faults and reset the system";
CM_ BO_ 2155937889  "Control the system flags";
CM_ BO_ 2155937810  "box commands";
CM_ BO_ 2155937811  "Converter power info";
CM_ BO_ 2155937808  "General Status of the converter";
CM_ BO_ 2155938032  "FSm status for debug";
CM_ BO_ 2155937809  "Fault bitfield";
CM_ BO_ 2155937813  "interface status";
CM_ BO_ 2155937814  "Configure the Heartbeat for the Module. The 'Trip interlock' and 'Heartbeat Period' only apply if the heartbeat signals are enabled";
CM_ BO_ 2155937815  "Readouts of the converter temperature sensors";
CM_ BO_ 2155937816  "Readouts of the converter fans";
CM_ BO_ 2155937817  "keep alive feeding";
CM_ BO_ 2155938033  "BOX interlock status used for debug ";
CM_ BO_ 2155937812  "Configure the broadcast group that the module belongs to.";
CM_ BO_ 2155937920  "Contains the Group ID of the device";
CM_ BO_ 2155937921  "Contains the Group ID of the device";
CM_ BO_ 2155937922  "Contains the Group ID of the device";
CM_ BO_ 2155937923  "Contains the Group ID of the device";
CM_ BO_ 2155937924  "Contains the Group ID of the device";
CM_ BO_ 2155937925  "Contains the Group ID of the device";
CM_ BO_ 2155937926  "Contains the Group ID of the device";
CM_ BO_ 2155937927  "Contains the Group ID of the device";
CM_ BO_ 2155937928  "Status of internal modules";
CM_ BO_ 2155937929  "Status of internal modules";
CM_ BO_ 2155937930  "Status of internal modules";
CM_ BO_ 2155937931  "Status of internal modules";
CM_ BO_ 2155937932  "Status of internal modules";
CM_ BO_ 2155937933  "Status of internal modules";
CM_ BO_ 2155937936  "Status of internal modules";
CM_ BO_ 2155937937  "debug - Allow to knwow  what module has wrong can api";
CM_ BO_ 2155937890  "Calibration control (factory mode need to be set)";
CM_ BO_ 2155937891  "Calibration reading cmd (factory mode need to be set)";
CM_ BO_ 2155937892  "Calibration reading cmd (factory mode need to be set)";
CM_ BO_ 2155937888  "factory setting of controller and boxs";
CM_ BO_ 2155937893  "factory debug cmd, need factory mode flag set to 1";

CM_ SG_ 2155937856 mode_0_AC01 "require mode";
CM_ SG_ 2155937857 mode_0_AC01 "actual mode";
CM_ SG_ 2155937858 CABLE_1_2_L1_0_AC01 "DMF1(1).L1  BP25(2).U mismatch";
CM_ SG_ 2155937858 CABLE_1_3_L1_0_AC01 "DMF1(1).L1  BP25(3).U mismatch";
CM_ SG_ 2155937858 CABLE_1_2_L2_0_AC01 "DMF1(1).L2  BP25(2).V mismatch";
CM_ SG_ 2155937858 CABLE_1_3_L2_0_AC01 "DMF1(1).L2  BP25(3).V mismatch";
CM_ SG_ 2155937858 CABLE_1_2_L3_0_AC01 "DMF1(1).L3  BP25(2).W mismatch";
CM_ SG_ 2155937858 CABLE_1_3_L3_0_AC01 "DMF1(1).L3  BP25(3).W mismatch";
CM_ SG_ 2155937858 CABLE_4_5_L1_0_AC01 "DMF1(4).L1  BP25(5).U mismatch";
CM_ SG_ 2155937858 CABLE_4_6_L1_0_AC01 "DMF1(4).L1  BP25(6).U mismatch";
CM_ SG_ 2155937858 CABLE_4_5_L2_0_AC01 "DMF1(4).L2  BP25(5).V mismatch";
CM_ SG_ 2155937858 CABLE_4_6_L2_0_AC01 "DMF1(4).L2  BP25(6).V mismatch";
CM_ SG_ 2155937858 CABLE_4_5_L3_0_AC01 "DMF1(4).L3  BP25(5).W mismatch";
CM_ SG_ 2155937858 CABLE_4_6_L3_0_AC01 "DMF1(4).L3  BP25(6).W mismatch";
CM_ SG_ 2155937858 CABLE_1_4_L1_0_AC01 "Grid L1  DMF1(1).in vs DMF1(4).in mismatch";
CM_ SG_ 2155937858 CABLE_1_4_L2_0_AC01 "Grid L2  DMF1(1).in vs DMF1(4).in mismatch";
CM_ SG_ 2155937858 CABLE_1_4_L3_0_AC01 "Grid L3 - DMF1(1).in vs DMF1(4).in mismatch";
CM_ SG_ 2155937858 CABLE_2_3_DC_0_AC01 "BP25(2).DC  BP25(3).DC mismatch";
CM_ SG_ 2155937858 CABLE_5_6_DC_0_AC01 "BP25(5).DC  BP25(6).DC mismatch";
CM_ SG_ 2155937858 CABLE_3_5_DC_0_AC01 "BP25(3).DC  BP25(5).DC mismatch";
CM_ SG_ 2155937858 MODULE_1_RUNNING_0_AC01 "DMF1(1) running error";
CM_ SG_ 2155937858 MODULE_2_RUNNING_0_AC01 "DMF1(2) running error";
CM_ SG_ 2155937858 MODULE_3_RUNNING_0_AC01 "DMF1(3) running error";
CM_ SG_ 2155937858 MODULE_4_RUNNING_0_AC01 "DMF1(4) running error";
CM_ SG_ 2155937858 MODULE_5_RUNNING_0_AC01 "DMF1(5) running error";
CM_ SG_ 2155937858 MODULE_6_RUNNING_0_AC01 "DMF1(6) running error";
CM_ SG_ 2155937858 FILTER_1_RELAY_FAIL_0_AC01 "Relay 1 fail";
CM_ SG_ 2155937858 FILTER_4_RELAY_FAIL_0_AC01 "Relay 4 fail";
CM_ SG_ 2155937858 FILTER_1_RELAY_NOT_OFF_0_AC01 "Relay 1 not off";
CM_ SG_ 2155937858 FILTER_4_RELAY_NOT_OFF_0_AC01 "Relay 4 not off";
CM_ SG_ 2155937858 PRECHARGE_RELAY_CLOSING_0_AC01 "Precharge relay closing";
CM_ SG_ 2155937858 PRECHARGE_RELAY_OPENING_0_AC01 "Precharge relay opening";
CM_ SG_ 2155937858 FILTER_NOT_RUNNING_0_AC01 "Filter not running";
CM_ SG_ 2155937858 RECTIFIER_3P_NOT_RUNNING_0_AC01 "Rectifier not running";
CM_ SG_ 2155937858 AFE_NOT_OFF_0_AC01 "AFE not off";
CM_ SG_ 2155937858 FILTER_STOP_RUNNING_0_AC01 "Filter stop running";
CM_ SG_ 2155937858 RECTIFIER_3P_STOP_RUNNING_0_AC01 "Rectifier stop running";
CM_ SG_ 2155937858 AFE_PWM_NOT_RUNNING_0_AC01 "BLEEDING not running";
CM_ SG_ 2155937858 AFE_PWM_STOP_RUNNING_0_AC01 "Bleeding stop running";
CM_ SG_ 2155937858 BLEEDING_FAILED_0_AC01 "Bleeding failed";
CM_ SG_ 2155937858 FILTER_NOT_OFF_0_AC01 "filter not off";
CM_ SG_ 2155937859 GHM_INIT_0_AC01 "GHM init failed";
CM_ SG_ 2155937859 GHM_RMS_0_AC01 "GHM RMS failed";
CM_ SG_ 2155937859 GHM_FREQ_0_AC01 "GHM freq failed";
CM_ SG_ 2155937859 GHM_PHASE_0_AC01 "GHM phase failed";
CM_ SG_ 2155937859 V_SET_DC_BELOW_AC_0_AC01 "DC voltage too low vs AC";
CM_ SG_ 2155937859 AFE_DROOP_NOT_ENABLE_0_AC01 "Group ID not set";
CM_ SG_ 2155937859 MODE_NOT_SUPPORTED_0_AC01 "Mode not supported";
CM_ SG_ 2155937859 V_A_LOW_0_AC01 "voltage port a too low";
CM_ SG_ 2155937859 V_A_HIGH_0_AC01 "voltage port a too high";
CM_ SG_ 2155937860 BLEEDING_DONE_0_AC01 "Current limited by power max ";
CM_ SG_ 2155937860 CURRENT_LIMIT_0_AC01 "Current limited by power max ";
CM_ SG_ 2155937860 CURRENT_LIMITED_BY_POWER_0_AC01 "Current limited by power max ";
CM_ SG_ 2155937860 VB_LIMITED_BY_VA_0_AC01 "VA is not high enough to reach targeted VB";
CM_ SG_ 2155937824 Voltage_0_AC01 "Control the target dc side voltage. This voltage will be maintained as long as the current required to do so is smaller than the current limits specified in this message";
CM_ SG_ 2155937824 Positive_Current_Limit_0_AC01 "The maximum current that the AC01 will source on the DC Port";
CM_ SG_ 2155937824 Negative_Current_Limit_0_AC01 "The maximum current that the AC01 will sink into the DC Port";
CM_ SG_ 2155937825 Voltage_0_AC01 "The voltage target of the DC port";
CM_ SG_ 2155937825 Positive_Current_Limit_0_AC01 "The maximum current that the AC01 will source on the DC Port";
CM_ SG_ 2155937825 Negative_Current_Limit_0_AC01 "The maximum amount of current that the AC01 will sink into the DC port";
CM_ SG_ 2155937828 Voltage_0_AC01 "Voltage on the DC Port";
CM_ SG_ 2155937828 Current_0_AC01 "Current through the DC Port";
CM_ SG_ 2155937826 Positive_Current_Droop_0_AC01 "The droop resistance to apply for current flowing out of the DC port (DC current is positive)";
CM_ SG_ 2155937826 Negative_Current_Droop_0_AC01 "The droop resistance to apply for current flowing in to the DC Port (DC current is negative)";
CM_ SG_ 2155937826 Enable_0_AC01 "Enable DC Droop. If this feature is enabled the output voltage of the DC port varies with output current.";
CM_ SG_ 2155937826 Reserved_0_AC01 "This space is reserved. This region should contain only '0's";
CM_ SG_ 2155937827 Positive_Current_Droop_0_AC01 "The droop resistance applied for current flowing out of the DC port (DC current is positive)";
CM_ SG_ 2155937827 Negative_Current_Droop_0_AC01 "The droop resistance applied for current flowing in to the DC Port (DC current is negative)";
CM_ SG_ 2155937827 Enable_0_AC01 "Show is DC Droop is enabled.";
CM_ SG_ 2155937827 Reserved_0_AC01 "This space is reserved. This region should contain only '0's";
CM_ SG_ 2155937842 Frequency_0_AC01 "RMS Voltage of L1";
CM_ SG_ 2155937842 Voltage_0_AC01 "Average RMS Line to Line voltage at the AC port";
CM_ SG_ 2155937842 Reserved_0_AC01 "This space is reserved. This region contains only '0's";
CM_ SG_ 2155937843 U_0_AC01 "RMS Voltage of L1";
CM_ SG_ 2155937843 I_0_AC01 "RMS Current of L1";
CM_ SG_ 2155937843 P_0_AC01 "Active power of L1";
CM_ SG_ 2155937843 Q_0_AC01 "Reactive power of L1";
CM_ SG_ 2155937844 U_0_AC01 "RMS Voltage of L1";
CM_ SG_ 2155937844 I_0_AC01 "RMS Current of L2";
CM_ SG_ 2155937844 P_0_AC01 "Active power of L2";
CM_ SG_ 2155937844 Q_0_AC01 "Reactive power of L2";
CM_ SG_ 2155937845 U_0_AC01 "RMS Voltage of L3";
CM_ SG_ 2155937845 I_0_AC01 "RMS Current of L3";
CM_ SG_ 2155937845 P_0_AC01 "Active power of L3";
CM_ SG_ 2155937845 Q_0_AC01 "Reactive power of L3";
CM_ SG_ 2155937840 Q_0_AC01 "Reactive Power of the AC port. Positive values cause the AC01 to behave inductively, negative values cause the AC01 to behave capacitively";
CM_ SG_ 2155937840 Reserved_0_AC01 "This space is reserved. This region should contain only 0s";
CM_ SG_ 2155937841 Q_0_AC01 "Reactive Power of the AC port. Positive values cause the AC01 to behave inductively, negative values cause the AC01 to behave capacitively";
CM_ SG_ 2155937841 Reserved_0_AC01 "This space is reserved. This region should contain only 0s";
CM_ SG_ 2155937792 Type_0_BASE "The device identification field, uniquely identifies the sender in the network";
CM_ SG_ 2155937792 Revision_0_BASE "The hardware revision number";
CM_ SG_ 2155937792 Variant_0_BASE "The hardware variant";
CM_ SG_ 2155937792 Stack_position_0_BASE "Position of the module within the stack";
CM_ SG_ 2155937792 serial_number_0_BASE "Unique module serial number";
CM_ SG_ 2155937795 Major_0_BASE "The Major version number. This number increases if there are backwards incompatible changes";
CM_ SG_ 2155937795 Minor_0_BASE "The Minor version number. This number increases if there are backwards compatible changes, like new messages or the use of previously reserved space";
CM_ SG_ 2155937795 Patch_0_BASE "The Patch number. This number increases when changes to descriptions and documentation/comments are made";
CM_ SG_ 2155937861 Stack_position_0_BASE "The module position within the stack";
CM_ SG_ 2155937861 reserved_0_BASE "was stack size before";
CM_ SG_ 2155937861 SN_number_0_BASE "Unique module serial number";
CM_ SG_ 2155937872 Clear_Interlock_0_BASE "Clears the converter interlock";
CM_ SG_ 2155937872 Reset_Processor_0_BASE "Reset the converter DSP";
CM_ SG_ 2155937872 Trip_Interlock_0_BASE "Trip the inetrnal Interlock";
CM_ SG_ 2155937872 Reserved_0_BASE "Reserved space";
CM_ SG_ 2155937889 Factory_mode_0_BASE "Customers MUST NOT USE this bit. If set to 1, module will enter in factory mode. ";
CM_ SG_ 2155937810 enable_0__BOX "Enable the system";
CM_ SG_ 2155937811 load_0__BOX "load in percent";
CM_ SG_ 2155937811 efficiency_0__BOX "load in percent";
CM_ SG_ 2155937811 Power_capability_0__BOX "Power capabilities in kw";
CM_ SG_ 2155937811 low_power_input_0__BOX "low power iunput voltage";
CM_ SG_ 2155937808 State_0__BOX "box state";
CM_ SG_ 2155937808 flag_enable_0__BOX "flag to know if the system is Enable";
CM_ SG_ 2155937808 flag_ready_0__BOX "box has receive correct set point and can be turned one ";
CM_ SG_ 2155937808 flag_energized_0__BOX "the box is energized ";
CM_ SG_ 2155937808 flag_busy_0__BOX "box is busy ";
CM_ SG_ 2155937808 flag_eco_0__BOX "box is in eco mode";
CM_ SG_ 2155937808 flag_warning_0__BOX "box has warning and might be in degraded mode ";
CM_ SG_ 2155937808 flag_degraded_0__BOX "box function in degraded mode ";
CM_ SG_ 2155937808 flag_error_0__BOX "box has error those need to ble cleared to allow operation ";
CM_ SG_ 2155937808 flag_factory_0__BOX "box function in factory mode ";
CM_ SG_ 2155937808 flag_god_mode_0__BOX "box function in degraded mode ";
CM_ SG_ 2155938032 init_0__BOX "box state init";
CM_ SG_ 2155938032 ready_0__BOX "box state ready";
CM_ SG_ 2155938032 turned_on_0__BOX "box state turned on";
CM_ SG_ 2155938032 turned_off_0__BOX "box state turned off";
CM_ SG_ 2155938032 bleeding_0__BOX "box state bleeding";
CM_ SG_ 2155937809 internal_0__BOX "This g is asserted if the interlock is open due to an internal fault condition (self-protection)";
CM_ SG_ 2155937809 external_0__BOX "This flag is asserted if the interlock is open due to an external condition received in the module.";
CM_ SG_ 2155937809 keep_alive_not_serv_internal_0__ " keep alive internal not served ";
CM_ SG_ 2155937809 error_temperature_0__BOX "trigger when a temperature has an errror";
CM_ SG_ 2155937809 internal_modules_can_api_0__BOX "internal module wrong API";
CM_ SG_ 2155937809 internal_modules_missing_0__BOX "internal modules missing";
CM_ SG_ 2155937809 internal_modules_wrong_0__BOX "internal modules wrong";
CM_ SG_ 2155937809 internal_modules_stack_0__BOX "internal modules stack error";
CM_ SG_ 2155937809 internal_modules_init_0__BOX "internal module failed init";
CM_ SG_ 2155937809 v_in_low_0__BOX "24v input too low ";
CM_ SG_ 2155937809 v_in_critical_0__BOX "24v input too low ";
CM_ SG_ 2155937809 keep_alive_not_serv_0__BOX " keep alive not served ";
CM_ SG_ 2155937813 Broadcast_Group_0__BOX "The broadcast group that the module belongs to. Broadcast group 0 implies that the module is not part of a broadcast group. ";
CM_ SG_ 2155937813 keep_Alive_0__BOX "keep alive requires the supervisory controller to send a heartbeat message at regular intervals";
CM_ SG_ 2155937813 reserved_0__BOX "If this signal and the 'keep alive' is enabled, violating the heartbeat will trip the interlock, shutting down all connected power converters";
CM_ SG_ 2155937813 keep_Alive_Period_0__BOX "The maximum period of the keep alive message. If the time between two heart-beat messages is longer than this value, the module ceases operation. This only applies when the Heartbeat signal is Enabled";
CM_ SG_ 2155937814 Enable_0__BOX "Enable/Disable the Heartbeat feature of the Module";
CM_ SG_ 2155937814 reserved_0__BOX "Set if the external interlock should be tripped if a heartbeat is not received within the configured period. If this signal is enabled the interlock is triped and the module is disabled. If this signal is set to Disabled, the interlock like will not be tripped but the module will cease operation";
CM_ SG_ 2155937814 Period_0__BOX "Set the maximum period of the Heartbeat message. If the time between two heart-beat messages is longer than this value, the module ceases operation.";
CM_ SG_ 2155937815 Cooling_plate_0__BOX "Temperature of the cooling plate";
CM_ SG_ 2155937815 Magnetics_0__BOX "Highest mesured temp of magnetics";
CM_ SG_ 2155937815 Transistors_0__BOX "Highest mesured temp of transistors";
CM_ SG_ 2155937815 RESERVED_0__BOX "Lowest measured temp internally";
CM_ SG_ 2155937816 A_rpm_0__BOX "Measured speed of Fan 1";
CM_ SG_ 2155937816 A_pwm_0__BOX "Fan speed in percentage (0 to 100%)";
CM_ SG_ 2155937816 B_rpm_0__BOX "Measured speed of Fan 1";
CM_ SG_ 2155937816 B_pwm_0__BOX "Fan speed in percentage (0 to 100%)";
CM_ SG_ 2155937817 feed_0__BOX "the value don't matter her tin order to feed the alive";
CM_ SG_ 2155937812 Group_ID_0__BOX "Broadcast Group that the module should monitor";
CM_ SG_ 2155937920 Type_0__BOX "The device identification field";
CM_ SG_ 2155937920 Revision_0__BOX "The hardware revision numbere";
CM_ SG_ 2155937920 Variant_0__BOX "Hardware variant";
CM_ SG_ 2155937920 reserved_0__BOX "Hardware variant";
CM_ SG_ 2155937920 serial_number_0__BOX "Hardware variant";
CM_ SG_ 2155937921 nb_detected_0__BOX "number of modules detectedce";
CM_ SG_ 2155937921 nd_side_a_0__BOX "number of modules detectedce";
CM_ SG_ 2155937921 nd_side_b_0__BOX "number of modules detectedce";
CM_ SG_ 2155937921 Collision_0__BOX "collision between module";
CM_ SG_ 2155937922 Type_0__BOX "The device identification field";
CM_ SG_ 2155937922 Revision_0__BOX "The hardware revision numbere";
CM_ SG_ 2155937922 Variant_0__BOX "Hardware variant";
CM_ SG_ 2155937922 Stack_position_0__BOX "Hardware variant";
CM_ SG_ 2155937922 serial_number_0__BOX "Hardware variant";
CM_ SG_ 2155937923 Type_0__BOX "The device identification field";
CM_ SG_ 2155937923 Revision_0__BOX "The hardware revision numbere";
CM_ SG_ 2155937923 Variant_0__BOX "Hardware variant";
CM_ SG_ 2155937923 Stack_position_0__BOX "Hardware variant";
CM_ SG_ 2155937923 serial_number_0__BOX "Hardware variant";
CM_ SG_ 2155937924 Type_0__BOX "The device identification field";
CM_ SG_ 2155937924 Revision_0__BOX "The hardware revision numbere";
CM_ SG_ 2155937924 Variant_0__BOX "Hardware variant";
CM_ SG_ 2155937924 Stack_position_0__BOX "Hardware variant";
CM_ SG_ 2155937924 serial_number_0__BOX "Hardware variant";
CM_ SG_ 2155937925 Type_0__BOX "The device identification field";
CM_ SG_ 2155937925 Revision_0__BOX "The hardware revision numbere";
CM_ SG_ 2155937925 Variant_0__BOX "Hardware variant";
CM_ SG_ 2155937925 Stack_position_0__BOX "Hardware variant";
CM_ SG_ 2155937925 serial_number_0__BOX "Hardware variant";
CM_ SG_ 2155937926 Type_0__BOX "The device identification field";
CM_ SG_ 2155937926 Revision_0__BOX "The hardware revision numbere";
CM_ SG_ 2155937926 Variant_0__BOX "Hardware variant";
CM_ SG_ 2155937926 Stack_position_0__BOX "Hardware variant";
CM_ SG_ 2155937926 serial_number_0__BOX "Hardware variant";
CM_ SG_ 2155937927 Type_0__BOX "The device identification field";
CM_ SG_ 2155937927 Revision_0__BOX "The hardware revision numbere";
CM_ SG_ 2155937927 Variant_0__BOX "Hardware variant";
CM_ SG_ 2155937927 Stack_position_0__BOX "Hardware variant";
CM_ SG_ 2155937927 serial_number_0__BOX "Hardware variant";
CM_ SG_ 2155937928 Available_0__BOX "The device available";
CM_ SG_ 2155937928 Side_0__BOX "The device is Ready";
CM_ SG_ 2155937928 Status_0__BOX "The device is Running";
CM_ SG_ 2155937928 Interlock_I_0__BOX "The device have interlock internal";
CM_ SG_ 2155937928 Interlock_E_0__BOX "The device have interlock external";
CM_ SG_ 2155937928 mode_0__BOX "Mode";
CM_ SG_ 2155937929 Available_0__BOX "The device available";
CM_ SG_ 2155937929 Side_0__BOX "The device is Ready";
CM_ SG_ 2155937929 Status_0__BOX "The device is Running";
CM_ SG_ 2155937929 Interlock_I_0__BOX "The device have interlock internal";
CM_ SG_ 2155937929 Interlock_E_0__BOX "The device have interlock external";
CM_ SG_ 2155937929 mode_0__BOX "Mode";
CM_ SG_ 2155937930 Available_0__BOX "The device available";
CM_ SG_ 2155937930 Side_0__BOX "The device is Ready";
CM_ SG_ 2155937930 Status_0__BOX "The device is Running";
CM_ SG_ 2155937930 Interlock_I_0__BOX "The device have interlock internal";
CM_ SG_ 2155937930 Interlock_E_0__BOX "The device have interlock external";
CM_ SG_ 2155937930 mode_0__BOX "Mode";
CM_ SG_ 2155937931 Available_0__BOX "The device available";
CM_ SG_ 2155937931 Side_0__BOX "The device is Ready";
CM_ SG_ 2155937931 Status_0__BOX "The device is Running";
CM_ SG_ 2155937931 Interlock_I_0__BOX "The device have interlock internal";
CM_ SG_ 2155937931 Interlock_E_0__BOX "The device have interlock external";
CM_ SG_ 2155937931 mode_0__BOX "Mode";
CM_ SG_ 2155937932 Available_0__BOX "The device available";
CM_ SG_ 2155937932 Side_0__BOX "The device is Ready";
CM_ SG_ 2155937932 Status_0__BOX "The device is Running";
CM_ SG_ 2155937932 Interlock_I_0__BOX "The device have interlock internal";
CM_ SG_ 2155937932 Interlock_E_0__BOX "The device have interlock external";
CM_ SG_ 2155937932 mode_0__BOX "Mode";
CM_ SG_ 2155937933 Available_0__BOX "The device available";
CM_ SG_ 2155937933 Side_0__BOX "The device is Ready";
CM_ SG_ 2155937933 Status_0__BOX "The device is Running";
CM_ SG_ 2155937933 Interlock_I_0__BOX "The device have interlock internal";
CM_ SG_ 2155937933 Interlock_E_0__BOX "The device have interlock external";
CM_ SG_ 2155937933 mode_0__BOX "Mode";
CM_ SG_ 2155937936 cpu_1_usage_0__BOX "Controller cpu 1 usage";
CM_ SG_ 2155937936 cpu_2_usage_0__BOX "Controller cpu 2 usage";
CM_ SG_ 2155937936 can_bus_load_A_0__BOX "Controller cup 1 usage";
CM_ SG_ 2155937936 can_bus_load_B_0__BOX "Controller cpu 1 usage";
CM_ SG_ 2155937936 main_loop_freq_0__BOX "Controller cpu 1 usage";
CM_ SG_ 2155937937 Type_0__BOX "The device identification field";
CM_ SG_ 2155937937 Stack_position_0__BOX "Hardware variant";
CM_ SG_ 2155937937 Major_expected_0__BOX "The Major version number. This number increases if there are backwards incompatible changes";
CM_ SG_ 2155937937 Minor_expected_0__BOX "The minor version number. This number increases if there are backwards incompatible changes";
CM_ SG_ 2155937937 Patch_expected_0__BOX "The patch version number. This number increases if there are backwards incompatible changes";
CM_ SG_ 2155937937 Major_actual_0__BOX "The Major version number. This number increases if there are backwards incompatible changes";
CM_ SG_ 2155937937 Minor_actual_0__BOX "The minor version number. This number increases if there are backwards incompatible changes";
CM_ SG_ 2155937937 Patch_actual_0__BOX "The patch version number. This number increases if there are backwards incompatible changes";
CM_ SG_ 2155937890 index_0__BOX "index of the device that nee calibration (0 is unvalid) ";
CM_ SG_ 2155937890 select_0__BOX "select what value to set";
CM_ SG_ 2155937890 value_0__BOX "require calibration valut ";
CM_ SG_ 2155937891 index_0__BOX "index of the device that need reading ";
CM_ SG_ 2155937891 select_0__BOX "select what value to read";
CM_ SG_ 2155937892 index_0__BOX "index of the device that need reading ";
CM_ SG_ 2155937892 select_0__BOX "select what value to read";
CM_ SG_ 2155937892 calibration_status_0__BOX "select what value to read";
CM_ SG_ 2155937892 reserved_0__BOX "select what value to read";
CM_ SG_ 2155937892 value_0__BOX "require calibration valut ";
CM_ SG_ 2155937888 select_0__BOX "set ID, need factory mode = 1 (will change revision and variant as well)";
CM_ SG_ 2155937888 set_id_0__BOX "set ID, need factory mode = 1 (will change revision and variant as well)";
CM_ SG_ 2155937888 set_revision_0__BOX "set revision, need factory mode = 1 , applied if set_id is valid";
CM_ SG_ 2155937888 set_variant_0__BOX "set variant, need factory mode = 1, applied if set_id is valid";
CM_ SG_ 2155937893 god_mode_0__BOX "Customers MUST NOT USE this bit. If set to 1, module will enter in factory mode. ";
CM_ SG_ 2155937893 internal_power_a_0__BOX "Customers MUST NOT USE this bit. If set to 1, module will enter in factory mode. ";
CM_ SG_ 2155937893 internal_power_b_0__BOX "Customers MUST NOT USE this bit. If set to 1, module will enter in factory mode. ";
CM_ SG_ 2155937893 offset_stack_internal_0__BOX "Customers MUST NOT USE this bit. need factory mode = 1 ";

BA_DEF_ BO_ "SystemMessageLongSymbol" STRING;
BA_DEF_ SG_ "SystemSignalLongSymbol" STRING;

BA_ "SystemMessageLongSymbol" BO_ 2155937827 "DC_Port_Applied_Droop_Setpoints_0_AC01";

BA_ "SystemSignalLongSymbol" SG_ 2155937809 Measurement_system_failure_0__BO "Measurement_system_failure_0__BOX";
BA_ "SystemSignalLongSymbol" SG_ 2155937809 keep_alive_not_serv_internal_0__ "keep_alive_not_serv_internal_0__BOX";

VAL_ 2155937856 mode_0_AC01 0 "DC_Controlled" 1 "AC_Controlled" 2 "Bleeding";
VAL_ 2155937857 mode_0_AC01 0 "DC_Controlled" 1 "AC_Controlled" 2 "Bleeding";
VAL_ 2155937858 CABLE_1_2_L1_0_AC01 0 "Clear" 1 "Critical";
VAL_ 2155937858 CABLE_1_3_L1_0_AC01 0 "Clear" 1 "Critical";
VAL_ 2155937858 CABLE_1_2_L2_0_AC01 0 "Clear" 1 "Critical";
VAL_ 2155937858 CABLE_1_3_L2_0_AC01 0 "Clear" 1 "Critical";
VAL_ 2155937858 CABLE_1_2_L3_0_AC01 0 "Clear" 1 "Critical";
VAL_ 2155937858 CABLE_1_3_L3_0_AC01 0 "Clear" 1 "Critical";
VAL_ 2155937858 CABLE_4_5_L1_0_AC01 0 "Clear" 1 "Critical";
VAL_ 2155937858 CABLE_4_6_L1_0_AC01 0 "Clear" 1 "Critical";
VAL_ 2155937858 CABLE_4_5_L2_0_AC01 0 "Clear" 1 "Critical";
VAL_ 2155937858 CABLE_4_6_L2_0_AC01 0 "Clear" 1 "Critical";
VAL_ 2155937858 CABLE_4_5_L3_0_AC01 0 "Clear" 1 "Critical";
VAL_ 2155937858 CABLE_4_6_L3_0_AC01 0 "Clear" 1 "Critical";
VAL_ 2155937858 CABLE_1_4_L1_0_AC01 0 "Clear" 1 "Critical";
VAL_ 2155937858 CABLE_1_4_L2_0_AC01 0 "Clear" 1 "Critical";
VAL_ 2155937858 CABLE_1_4_L3_0_AC01 0 "Clear" 1 "Critical";
VAL_ 2155937858 CABLE_2_3_DC_0_AC01 0 "Clear" 1 "Critical";
VAL_ 2155937858 CABLE_5_6_DC_0_AC01 0 "Clear" 1 "Critical";
VAL_ 2155937858 CABLE_3_5_DC_0_AC01 0 "Clear" 1 "Critical";
VAL_ 2155937858 MODULE_1_RUNNING_0_AC01 0 "Clear" 1 "Error";
VAL_ 2155937858 MODULE_2_RUNNING_0_AC01 0 "Clear" 1 "Error";
VAL_ 2155937858 MODULE_3_RUNNING_0_AC01 0 "Clear" 1 "Error";
VAL_ 2155937858 MODULE_4_RUNNING_0_AC01 0 "Clear" 1 "Error";
VAL_ 2155937858 MODULE_5_RUNNING_0_AC01 0 "Clear" 1 "Error";
VAL_ 2155937858 MODULE_6_RUNNING_0_AC01 0 "Clear" 1 "Error";
VAL_ 2155937858 FILTER_1_RELAY_FAIL_0_AC01 0 "Clear" 1 "Error";
VAL_ 2155937858 FILTER_4_RELAY_FAIL_0_AC01 0 "Clear" 1 "Error";
VAL_ 2155937858 FILTER_1_RELAY_NOT_OFF_0_AC01 0 "Clear" 1 "Error";
VAL_ 2155937858 FILTER_4_RELAY_NOT_OFF_0_AC01 0 "Clear" 1 "Error";
VAL_ 2155937858 PRECHARGE_RELAY_CLOSING_0_AC01 0 "Clear" 1 "Error";
VAL_ 2155937858 PRECHARGE_RELAY_OPENING_0_AC01 0 "Clear" 1 "Error";
VAL_ 2155937858 FILTER_NOT_RUNNING_0_AC01 0 "Clear" 1 "Error";
VAL_ 2155937858 RECTIFIER_3P_NOT_RUNNING_0_AC01 0 "Clear" 1 "Error";
VAL_ 2155937858 AFE_NOT_OFF_0_AC01 0 "Clear" 1 "Error";
VAL_ 2155937858 FILTER_STOP_RUNNING_0_AC01 0 "Clear" 1 "Error";
VAL_ 2155937858 RECTIFIER_3P_STOP_RUNNING_0_AC01 0 "Clear" 1 "Error";
VAL_ 2155937858 AFE_PWM_NOT_RUNNING_0_AC01 0 "Clear" 1 "Error";
VAL_ 2155937858 AFE_PWM_STOP_RUNNING_0_AC01 0 "Clear" 1 "Error";
VAL_ 2155937858 BLEEDING_FAILED_0_AC01 0 "Clear" 1 "Error";
VAL_ 2155937858 FILTER_NOT_OFF_0_AC01 0 "Clear" 1 "Error";
VAL_ 2155937859 GHM_INIT_0_AC01 0 "Clear" 1 "Warning";
VAL_ 2155937859 GHM_RMS_0_AC01 0 "Clear" 1 "Warning";
VAL_ 2155937859 GHM_FREQ_0_AC01 0 "Clear" 1 "Warning";
VAL_ 2155937859 GHM_PHASE_0_AC01 0 "Clear" 1 "Warning";
VAL_ 2155937859 V_SET_DC_BELOW_AC_0_AC01 0 "Clear" 1 "Warning";
VAL_ 2155937859 AFE_DROOP_NOT_ENABLE_0_AC01 0 "Clear" 1 "Warning";
VAL_ 2155937859 MODE_NOT_SUPPORTED_0_AC01 0 "Clear" 1 "Warning";
VAL_ 2155937859 V_A_LOW_0_AC01 0 "Clear" 1 "Warning";
VAL_ 2155937859 V_A_HIGH_0_AC01 0 "Clear" 1 "Warning";
VAL_ 2155937860 BLEEDING_DONE_0_AC01 0 "Clear" 1 "Info";
VAL_ 2155937860 CURRENT_LIMIT_0_AC01 0 "Clear" 1 "Info";
VAL_ 2155937860 CURRENT_LIMITED_BY_POWER_0_AC01 0 "Clear" 1 "Info";
VAL_ 2155937860 VB_LIMITED_BY_VA_0_AC01 0 "Clear" 1 "Info";
VAL_ 2155937826 Enable_0_AC01 0 "Disabled" 1 "Enabled";
VAL_ 2155937827 Enable_0_AC01 0 "Disabled" 1 "Enabled";
VAL_ 2155937792 Type_0_BASE 128 "GC01" 129 "AC01" 130 "DC01";
VAL_ 2155937792 Revision_0_BASE 0 "R0A" 1 "R0B" 2 "R0C";
VAL_ 2155937792 Variant_0_BASE 0 "VA00" 1 "VA01";
VAL_ 2155937808 State_0__BOX 0 "init" 1 "standby" 2 "turning_on" 3 "running" 4 "turning_off" 5 "error" 6 "critical" 7 "god";
VAL_ 2155937809 internal_0__BOX 0 "Clear" 1 "Tripped";
VAL_ 2155937809 external_0__BOX 0 "Clear" 1 "Tripped";
VAL_ 2155937809 system_0__BOX 0 "Clear" 1 "Critical";
VAL_ 2155937809 EEPROM_failure_0__BOX 0 "Clear" 1 "Critical";
VAL_ 2155937809 wrong_nfo_0__BOX 0 "Clear" 1 "Critical";
VAL_ 2155937809 Measurement_system_failure_0__BO 0 "Clear" 1 "Warning";
VAL_ 2155937809 PLL_not_locked_0__BOX 0 "Clear" 1 "Critical";
VAL_ 2155937809 overtemperature_0__BOX 0 "Clear" 1 "Error";
VAL_ 2155937809 fan_stuck_0__BOX 0 "Clear" 1 "Warning";
VAL_ 2155937809 dead_module_0__BOX 0 "Clear" 1 "Error";
VAL_ 2155937809 keep_alive_not_serv_internal_0__ 0 "Clear" 1 "Error";
VAL_ 2155937809 error_temperature_0__BOX 0 "Clear" 1 "Info";
VAL_ 2155937809 internal_modules_ready_0__BOX 0 "Clear" 1 "Error";
VAL_ 2155937809 internal_modules_can_api_0__BOX 0 "Clear" 1 "Critical";
VAL_ 2155937809 internal_modules_missing_0__BOX 0 "Clear" 1 "Critical";
VAL_ 2155937809 internal_modules_wrong_0__BOX 0 "Clear" 1 "Critical";
VAL_ 2155937809 internal_modules_stack_0__BOX 0 "Clear" 1 "Critical";
VAL_ 2155937809 internal_modules_init_0__BOX 0 "Clear" 1 "Error";
VAL_ 2155937809 wrong_revision_0__BOX 0 "Clear" 1 "Critical";
VAL_ 2155937809 v_in_low_0__BOX 0 "Clear" 1 "Error";
VAL_ 2155937809 v_in_critical_0__BOX 0 "Clear" 1 "Critical";
VAL_ 2155937809 keep_alive_not_serv_0__BOX 0 "Clear" 1 "Error";
VAL_ 2155937813 keep_Alive_0__BOX 0 "Disabled" 1 "Enabled";
VAL_ 2155937813 reserved_0__BOX 0 "Disabled" 1 "Enabled";
VAL_ 2155937814 Enable_0__BOX 0 "Disabled" 1 "Enabled";
VAL_ 2155937814 reserved_0__BOX 0 "Disabled" 1 "Enabled";
VAL_ 2155938033 e_0__BOX 0 "Tripped" 1 "Clear";
VAL_ 2155938033 a_0__BOX 0 "Tripped" 1 "Clear";
VAL_ 2155938033 b_0__BOX 0 "Tripped" 1 "Clear";
VAL_ 2155938033 i_0__BOX 0 "Tripped" 1 "Clear";
VAL_ 2155938033 x_0__BOX 0 "Tripped" 1 "Clear";
VAL_ 2155937920 Type_0__BOX 16 "GC01";
VAL_ 2155937922 Type_0__BOX 7 "BP25" 8 "BI25" 19 "DMF1";
VAL_ 2155937923 Type_0__BOX 7 "BP25" 8 "BI25" 19 "DMF1";
VAL_ 2155937924 Type_0__BOX 7 "BP25" 8 "BI25" 19 "DMF1";
VAL_ 2155937925 Type_0__BOX 7 "BP25" 8 "BI25" 19 "DMF1";
VAL_ 2155937926 Type_0__BOX 7 "BP25" 8 "BI25" 19 "DMF1";
VAL_ 2155937927 Type_0__BOX 7 "BP25" 8 "BI25" 19 "DMF1";
VAL_ 2155937928 Side_0__BOX 0 "side_unk" 1 "side_a" 2 "side_b";
VAL_ 2155937928 Status_0__BOX 0 "off" 1 "ready" 2 "running";
VAL_ 2155937929 Side_0__BOX 0 "side_unk" 1 "side_a" 2 "side_b";
VAL_ 2155937929 Status_0__BOX 0 "off" 1 "ready" 2 "running";
VAL_ 2155937930 Side_0__BOX 0 "side_unk" 1 "side_a" 2 "side_b";
VAL_ 2155937930 Status_0__BOX 0 "off" 1 "ready" 2 "running";
VAL_ 2155937931 Side_0__BOX 0 "side_unk" 1 "side_a" 2 "side_b";
VAL_ 2155937931 Status_0__BOX 0 "off" 1 "ready" 2 "running";
VAL_ 2155937932 Side_0__BOX 0 "side_unk" 1 "side_a" 2 "side_b";
VAL_ 2155937932 Status_0__BOX 0 "off" 1 "ready" 2 "running";
VAL_ 2155937933 Side_0__BOX 0 "side_unk" 1 "side_a" 2 "side_b";
VAL_ 2155937933 Status_0__BOX 0 "off" 1 "ready" 2 "running";
VAL_ 2155937937 Type_0__BOX 7 "BP25" 8 "BI25" 19 "DMF1";
VAL_ 2155937890 index_0__BOX 0 "invalid" 1 "voltage_sensor_b";
VAL_ 2155937890 select_0__BOX 0 "invalid" 1 "prob_offset" 2 "prob_scale_factor";
VAL_ 2155937891 index_0__BOX 0 "invalid" 1 "voltage_sensor_b";
VAL_ 2155937891 select_0__BOX 0 "raw" 1 "value" 2 "prob_offset" 3 "prob_scale_factor";
VAL_ 2155937892 index_0__BOX 0 "unvalid" 1 "voltage_sensor_b";
VAL_ 2155937892 select_0__BOX 0 "raw" 1 "value" 2 "prob_offset" 3 "prob_scale_factor";
VAL_ 2155937892 calibration_status_0__BOX 0 "bad" 1 "ok";
VAL_ 2155937888 select_0__BOX 0 "invalid" 1 "cs" 2 "adb" 3 "reset";
VAL_ 2155937893 internal_power_a_0__BOX 0 "on" 1 "off";
VAL_ 2155937893 internal_power_b_0__BOX 0 "on" 1 "off";
